# iostr910f register map
Registers are 32-bit, access not given, no defined reset value unless marked. A register's access mark holds for its fields unless they carry their own. Addresses are absolute; registers are grouped by the start of their names; [hi:lo] are bit positions; {n}, {i} and the like mark numbered series; 'fields as' and 'values as' point back to an identical list.

## UART2
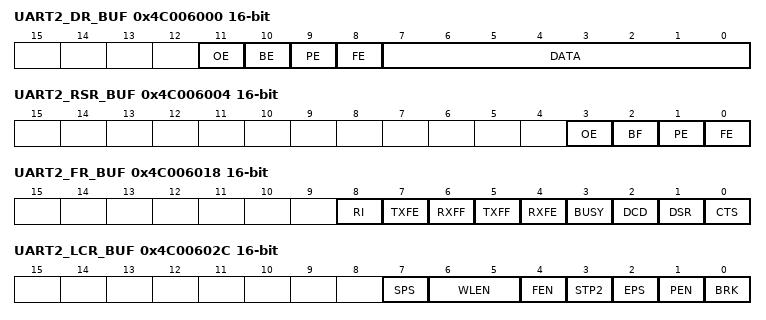
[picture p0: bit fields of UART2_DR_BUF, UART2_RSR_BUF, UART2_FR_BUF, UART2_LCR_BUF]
0x4C006000 UART2_DR_BUF 16-bit
  [11] OE, [10] BE, [9] PE, [8] FE, [7:0] DATA
0x4C006004 UART2_RSR_BUF 16-bit
  [3] OE, [2] BF, [1] PE, [0] FE
0x4C006018 UART2_FR_BUF 16-bit
  [8] RI, [7] TXFE, [6] RXFF, [5] TXFF, [4] RXFE, [3] BUSY, [2] DCD, [1] DSR, [0] CTS
0x4C006020 UART2_ILPR_BUF 8-bit
0x4C006024 UART2_IBRD_BUF 16-bit
0x4C006028 UART2_FBRD_BUF 16-bit
  [5:0] BAUD_DIVFRAC
0x4C00602C UART2_LCR_BUF 16-bit
  [7] SPS, [6:5] WLEN, [4] FEN, [3] STP2, [2] EPS, [1] PEN, [0] BRK
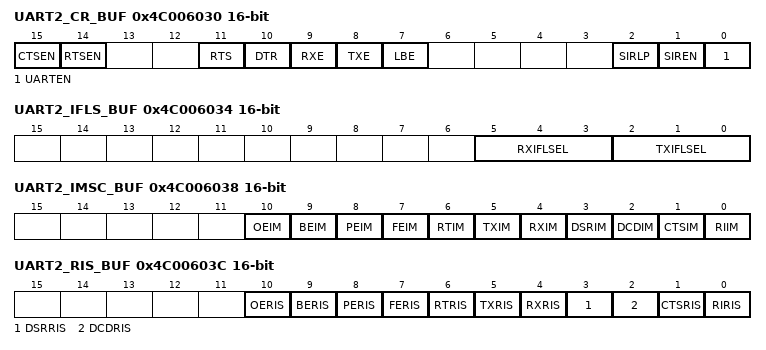
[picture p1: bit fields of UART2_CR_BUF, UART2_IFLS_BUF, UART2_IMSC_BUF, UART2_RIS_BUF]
0x4C006030 UART2_CR_BUF 16-bit
  [15] CTSEN, [14] RTSEN, [11] RTS, [10] DTR, [9] RXE, [8] TXE, [7] LBE, [2] SIRLP, [1] SIREN, [0] UARTEN
0x4C006034 UART2_IFLS_BUF 16-bit
  [5:3] RXIFLSEL, [2:0] TXIFLSEL
0x4C006038 UART2_IMSC_BUF 16-bit
  [10] OEIM, [9] BEIM, [8] PEIM, [7] FEIM, [6] RTIM, [5] TXIM, [4] RXIM, [3] DSRIM, [2] DCDIM, [1] CTSIM, [0] RIIM
0x4C00603C UART2_RIS_BUF 16-bit
  [10] OERIS, [9] BERIS, [8] PERIS, [7] FERIS, [6] RTRIS, [5] TXRIS, [4] RXRIS, [3] DSRRIS, [2] DCDRIS, [1] CTSRIS, [0] RIRIS
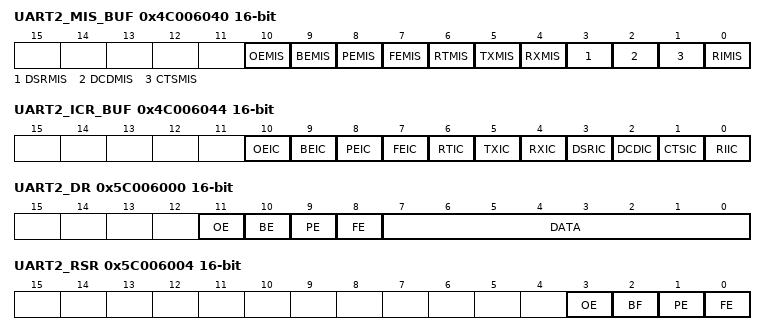
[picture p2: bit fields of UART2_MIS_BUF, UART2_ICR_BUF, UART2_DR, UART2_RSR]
0x4C006040 UART2_MIS_BUF 16-bit
  [10] OEMIS, [9] BEMIS, [8] PEMIS, [7] FEMIS, [6] RTMIS, [5] TXMIS, [4] RXMIS, [3] DSRMIS, [2] DCDMIS, [1] CTSMIS, [0] RIMIS
0x4C006044 UART2_ICR_BUF 16-bit
  [10] OEIC, [9] BEIC, [8] PEIC, [7] FEIC, [6] RTIC, [5] TXIC, [4] RXIC, [3] DSRIC, [2] DCDIC, [1] CTSIC, [0] RIIC
0x5C006000 UART2_DR 16-bit
  [11] OE, [10] BE, [9] PE, [8] FE, [7:0] DATA
0x5C006004 UART2_RSR 16-bit
  [3] OE, [2] BF, [1] PE, [0] FE
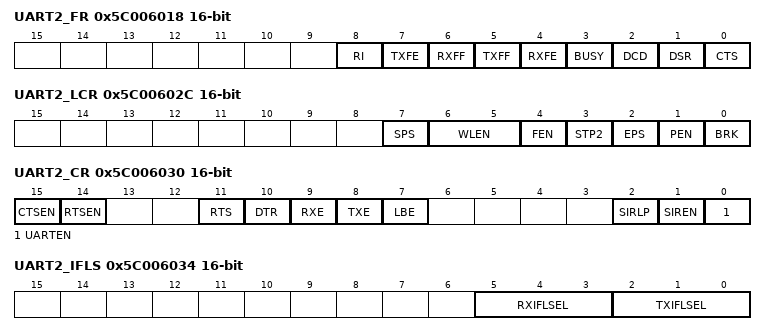
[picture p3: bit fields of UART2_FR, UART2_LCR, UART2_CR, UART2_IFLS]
0x5C006018 UART2_FR 16-bit
  fields as UART2_FR_BUF
0x5C006020 UART2_ILPR 8-bit
0x5C006024 UART2_IBRD 16-bit
0x5C006028 UART2_FBRD 16-bit
  [5:0] BAUD_DIVFRAC
0x5C00602C UART2_LCR 16-bit
  [7] SPS, [6:5] WLEN, [4] FEN, [3] STP2, [2] EPS, [1] PEN, [0] BRK
0x5C006030 UART2_CR 16-bit
  fields as UART2_CR_BUF
0x5C006034 UART2_IFLS 16-bit
  [5:3] RXIFLSEL, [2:0] TXIFLSEL
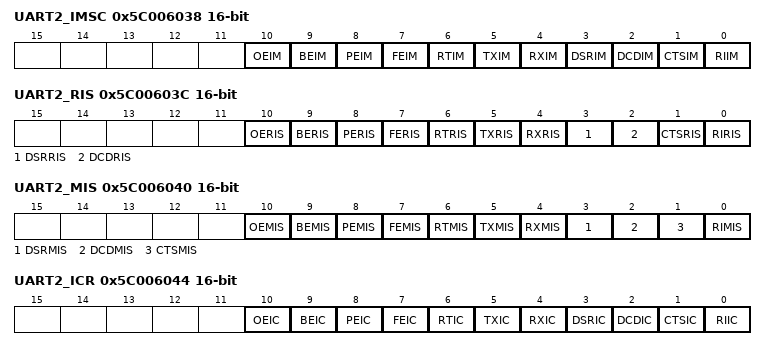
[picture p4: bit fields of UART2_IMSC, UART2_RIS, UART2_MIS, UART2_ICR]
0x5C006038 UART2_IMSC 16-bit
  fields as UART2_IMSC_BUF
0x5C00603C UART2_RIS 16-bit
  fields as UART2_RIS_BUF
0x5C006040 UART2_MIS 16-bit
  fields as UART2_MIS_BUF
0x5C006044 UART2_ICR 16-bit
  fields as UART2_ICR_BUF

## I2C0
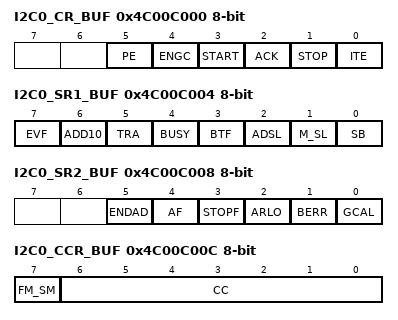
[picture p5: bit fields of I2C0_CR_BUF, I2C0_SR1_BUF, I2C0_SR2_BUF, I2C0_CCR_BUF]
0x4C00C000 I2C0_CR_BUF 8-bit
  [5] PE, [4] ENGC, [3] START, [2] ACK, [1] STOP, [0] ITE
0x4C00C004 I2C0_SR1_BUF 8-bit
  [7] EVF, [6] ADD10, [5] TRA, [4] BUSY, [3] BTF, [2] ADSL, [1] M_SL, [0] SB
0x4C00C008 I2C0_SR2_BUF 8-bit
  [5] ENDAD, [4] AF, [3] STOPF, [2] ARLO, [1] BERR, [0] GCAL
0x4C00C00C I2C0_CCR_BUF 8-bit
  [7] FM_SM, [6:0] CC
0x4C00C010 I2C0_OAR1_BUF 8-bit
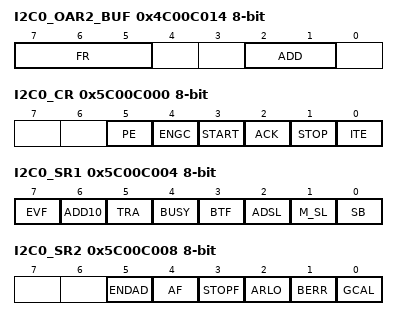
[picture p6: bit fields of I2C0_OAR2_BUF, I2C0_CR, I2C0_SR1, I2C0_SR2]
0x4C00C014 I2C0_OAR2_BUF 8-bit
  [7:5] FR, [2:1] ADD
0x4C00C018 I2C0_DR_BUF 8-bit
0x4C00C01C I2C0_ECCR_BUF 8-bit
  [4:0] CC
0x5C00C000 I2C0_CR 8-bit
  [5] PE, [4] ENGC, [3] START, [2] ACK, [1] STOP, [0] ITE
0x5C00C004 I2C0_SR1 8-bit
  fields as I2C0_SR1_BUF
0x5C00C008 I2C0_SR2 8-bit
  [5] ENDAD, [4] AF, [3] STOPF, [2] ARLO, [1] BERR, [0] GCAL
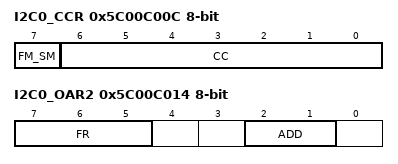
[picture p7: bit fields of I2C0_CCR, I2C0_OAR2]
0x5C00C00C I2C0_CCR 8-bit
  [7] FM_SM, [6:0] CC
0x5C00C010 I2C0_OAR1 8-bit
0x5C00C014 I2C0_OAR2 8-bit
  [7:5] FR, [2:1] ADD
0x5C00C018 I2C0_DR 8-bit
0x5C00C01C I2C0_ECCR 8-bit
  [4:0] CC

## I2C1
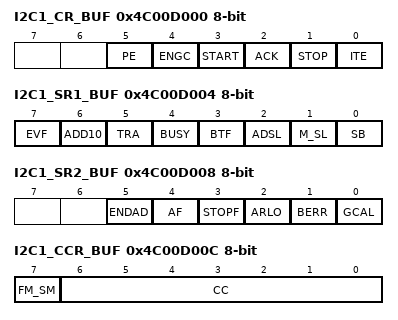
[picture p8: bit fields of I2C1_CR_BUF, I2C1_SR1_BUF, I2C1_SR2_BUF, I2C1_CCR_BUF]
0x4C00D000 I2C1_CR_BUF 8-bit
  [5] PE, [4] ENGC, [3] START, [2] ACK, [1] STOP, [0] ITE
0x4C00D004 I2C1_SR1_BUF 8-bit
  [7] EVF, [6] ADD10, [5] TRA, [4] BUSY, [3] BTF, [2] ADSL, [1] M_SL, [0] SB
0x4C00D008 I2C1_SR2_BUF 8-bit
  [5] ENDAD, [4] AF, [3] STOPF, [2] ARLO, [1] BERR, [0] GCAL
0x4C00D00C I2C1_CCR_BUF 8-bit
  [7] FM_SM, [6:0] CC
0x4C00D010 I2C1_OAR1_BUF 8-bit
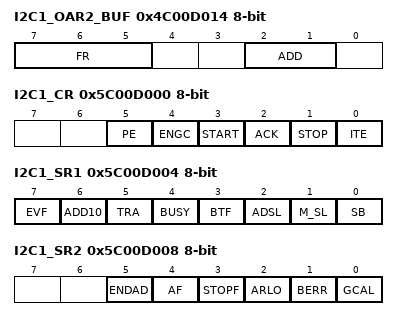
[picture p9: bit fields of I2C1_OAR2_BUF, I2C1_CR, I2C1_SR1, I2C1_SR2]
0x4C00D014 I2C1_OAR2_BUF 8-bit
  [7:5] FR, [2:1] ADD
0x4C00D018 I2C1_DR_BUF 8-bit
0x4C00D01C I2C1_ECCR_BUF 8-bit
  [4:0] CC
0x5C00D000 I2C1_CR 8-bit
  [5] PE, [4] ENGC, [3] START, [2] ACK, [1] STOP, [0] ITE
0x5C00D004 I2C1_SR1 8-bit
  fields as I2C1_SR1_BUF
0x5C00D008 I2C1_SR2 8-bit
  [5] ENDAD, [4] AF, [3] STOPF, [2] ARLO, [1] BERR, [0] GCAL
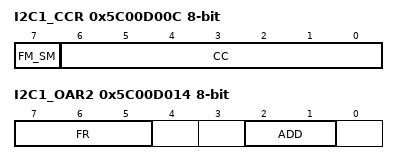
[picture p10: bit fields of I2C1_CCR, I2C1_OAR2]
0x5C00D00C I2C1_CCR 8-bit
  [7] FM_SM, [6:0] CC
0x5C00D010 I2C1_OAR1 8-bit
0x5C00D014 I2C1_OAR2 8-bit
  [7:5] FR, [2:1] ADD
0x5C00D018 I2C1_DR 8-bit
0x5C00D01C I2C1_ECCR 8-bit
  [4:0] CC

## MC
0x4C003000 MC_TCPT_BUF 16-bit
0x4C003004 MC_TCMP_BUF 8-bit
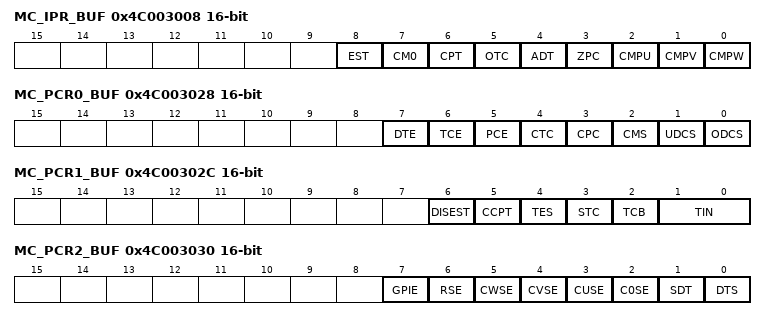
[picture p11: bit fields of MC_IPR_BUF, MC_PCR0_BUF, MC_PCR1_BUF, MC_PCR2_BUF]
0x4C003008 MC_IPR_BUF 16-bit
  [8] EST, [7] CM0, [6] CPT, [5] OTC, [4] ADT, [3] ZPC, [2] CMPU, [1] CMPV, [0] CMPW
0x4C00300C MC_TPRS_BUF 16-bit
  [11:0] TPRS
0x4C003010 MC_CPRS_BUF 8-bit
0x4C003014 MC_REP_BUF 8-bit
0x4C003018 MC_CMPW_BUF 16-bit
  [10:0] CMPW
0x4C00301C MC_CMPV_BUF 16-bit
  [10:0] CMPV
0x4C003020 MC_CMPU_BUF 16-bit
  [10:0] CMPU
0x4C003024 MC_CMP0_BUF 16-bit
  [9:0] CMP0
0x4C003028 MC_PCR0_BUF 16-bit
  [7] DTE, [6] TCE, [5] PCE, [4] CTC, [3] CPC, [2] CMS, [1] UDCS, [0] ODCS
0x4C00302C MC_PCR1_BUF 16-bit
  [6] DISEST, [5] CCPT, [4] TES, [3] STC, [2] TCB, [1:0] TIN
0x4C003030 MC_PCR2_BUF 16-bit
  [7] GPIE, [6] RSE, [5] CWSE, [4] CVSE, [3] CUSE, [2] C0SE, [1] SDT, [0] DTS
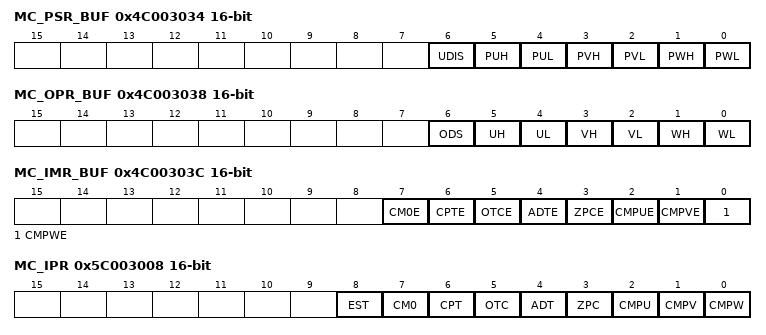
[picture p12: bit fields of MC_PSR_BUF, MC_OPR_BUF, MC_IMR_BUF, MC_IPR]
0x4C003034 MC_PSR_BUF 16-bit
  [6] UDIS, [5] PUH, [4] PUL, [3] PVH, [2] PVL, [1] PWH, [0] PWL
0x4C003038 MC_OPR_BUF 16-bit
  [6] ODS, [5] UH, [4] UL, [3] VH, [2] VL, [1] WH, [0] WL
0x4C00303C MC_IMR_BUF 16-bit
  [7] CM0E, [6] CPTE, [5] OTCE, [4] ADTE, [3] ZPCE, [2] CMPUE, [1] CMPVE, [0] CMPWE
0x4C003040 MC_DTG_BUF 16-bit
  [5:0] DTG
0x4C003044 MC_ESC_BUF 16-bit
0x5C003000 MC_TCPT 16-bit
0x5C003004 MC_TCMP 8-bit
0x5C003008 MC_IPR 16-bit
  fields as MC_IPR_BUF
0x5C00300C MC_TPRS 16-bit
  [11:0] TPRS
0x5C003010 MC_CPRS 8-bit
0x5C003014 MC_REP 8-bit
0x5C003018 MC_CMPW 16-bit
  [10:0] CMPW
0x5C00301C MC_CMPV 16-bit
  [10:0] CMPV
0x5C003020 MC_CMPU 16-bit
  [10:0] CMPU
0x5C003024 MC_CMP0 16-bit
  [9:0] CMP0
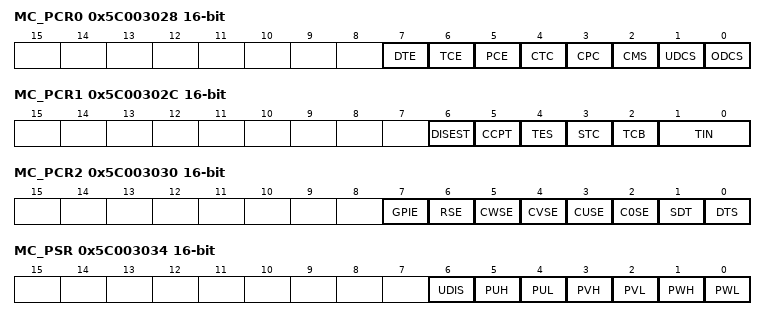
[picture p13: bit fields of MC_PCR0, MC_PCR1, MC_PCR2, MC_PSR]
0x5C003028 MC_PCR0 16-bit
  fields as MC_PCR0_BUF
0x5C00302C MC_PCR1 16-bit
  [6] DISEST, [5] CCPT, [4] TES, [3] STC, [2] TCB, [1:0] TIN
0x5C003030 MC_PCR2 16-bit
  fields as MC_PCR2_BUF
0x5C003034 MC_PSR 16-bit
  [6] UDIS, [5] PUH, [4] PUL, [3] PVH, [2] PVL, [1] PWH, [0] PWL
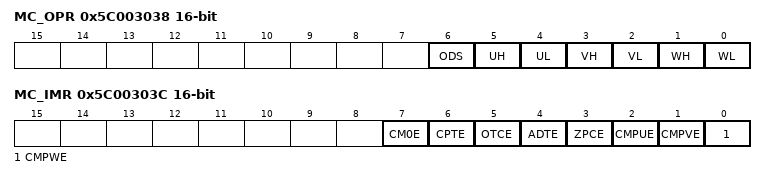
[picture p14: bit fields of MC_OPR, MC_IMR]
0x5C003038 MC_OPR 16-bit
  [6] ODS, [5] UH, [4] UL, [3] VH, [2] VL, [1] WH, [0] WL
0x5C00303C MC_IMR 16-bit
  fields as MC_IMR_BUF
0x5C003040 MC_DTG 16-bit
  [5:0] DTG
0x5C003044 MC_ESC 16-bit

## ADC
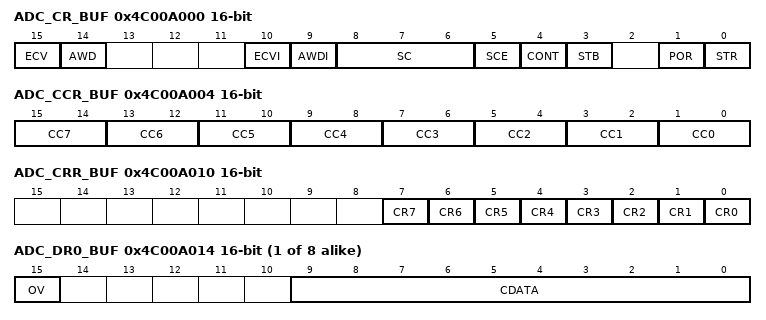
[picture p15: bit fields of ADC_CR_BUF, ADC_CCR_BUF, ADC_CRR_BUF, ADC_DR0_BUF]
0x4C00A000 ADC_CR_BUF 16-bit
  [15] ECV, [14] AWD, [10] ECVI, [9] AWDI, [8:6] SC, [5] SCE, [4] CONT, [3] STB, [1] POR, [0] STR
0x4C00A004 ADC_CCR_BUF 16-bit
  [2n+1:2n] CC{n} (n=0..7)
0x4C00A008 ADC_HTR_BUF 16-bit
  [9:0] HT
0x4C00A00C ADC_LTR_BUF 16-bit
  [9:0] LT
0x4C00A010 ADC_CRR_BUF 16-bit
  [n] CR{n} (n=0..7)
{0x4C00A014+4i} ADC_DR{i}_BUF 16-bit (i=0..7)
  [15] OV, [9:0] CDATA
0x4C00A034 ADC_PRS_BUF 8-bit
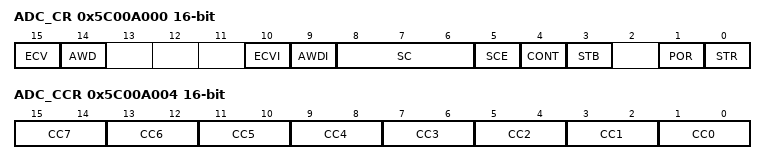
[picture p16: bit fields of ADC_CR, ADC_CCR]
0x5C00A000 ADC_CR 16-bit
  fields as ADC_CR_BUF
0x5C00A004 ADC_CCR 16-bit
  [2n+1:2n] CC{n} (n=0..7)
0x5C00A008 ADC_HTR 16-bit
  [9:0] HT
0x5C00A00C ADC_LTR 16-bit
  [9:0] LT
0x5C00A010 ADC_CRR 16-bit
  [n] CR{n} (n=0..7)
{0x5C00A014+4i} ADC_DR{i} 16-bit (i=0..7)
  [15] OV, [9:0] CDATA
0x5C00A034 ADC_PRS 8-bit

## APB
0x48000000 APB_BSR_BUF
  [5] APBT, [4] OUTM, [0] ERROR
0x48000004 APB_BCR_BUF
  [24] SPLITEN, [20:16] SPLIT_CNT, [8] ERREN, [4:0] TOUT_CNT
0x48000008 APB_PAER_BUF
  [24] RW, [23:0] PERIPHERAL_ADDRESS
0x58000000 APB_BSR
  [5] APBT, [4] OUTM, [0] ERROR
0x58000004 APB_BCR
  [24] SPLITEN, [20:16] SPLIT_CNT, [8] ERREN, [4:0] TOUT_CNT
0x58000008 APB_PAER
  [24] RW, [23:0] PERIPHERAL_ADDRESS
